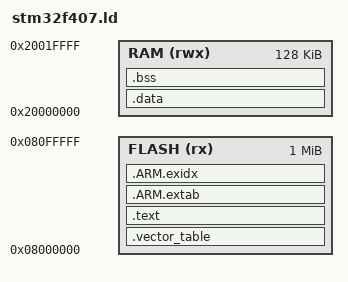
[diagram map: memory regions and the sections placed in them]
MEMORY
{
  FLASH (rx) : ORIGIN = 0x08000000, LENGTH = 1024K
  RAM (rwx)  : ORIGIN = 0x20000000, LENGTH = 128K
}

_estack = ORIGIN(RAM) + LENGTH(RAM);

SECTIONS
{
  .vector_table :
  {
    KEEP(*(.vector_table))
  } > FLASH

  .text :
  {
    *(.text*)
    *(.rodata*)
  } > FLASH

  .ARM.extab :
  {
    *(.ARM.extab* .gnu.linkonce.armextab.*)
  } > FLASH

  .ARM.exidx :
  {
    __exidx_start = .;
    *(.ARM.exidx* .gnu.linkonce.armexidx.*)
    __exidx_end = .;
  } > FLASH

  .data : AT(ADDR(.ARM.exidx) + SIZEOF(.ARM.exidx))
  {
    _sdata = .;
    *(.data*)
    _edata = .;
  } > RAM

  .bss :
  {
    _sbss = .;
    *(.bss*)
    *(COMMON)
    _ebss = .;
  } > RAM

  _sidata = LOADADDR(.data);
}
